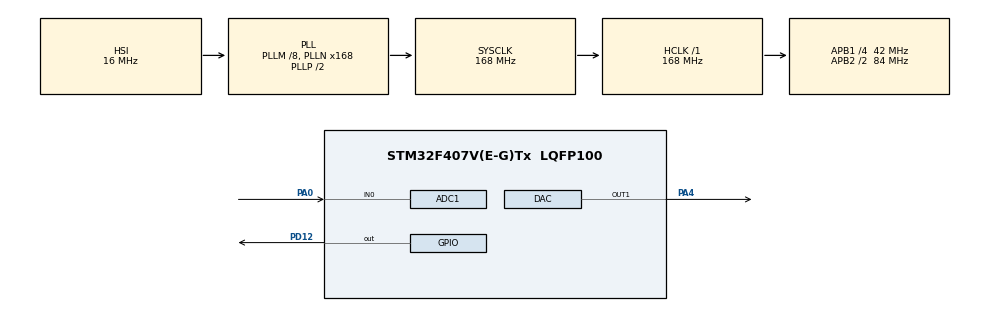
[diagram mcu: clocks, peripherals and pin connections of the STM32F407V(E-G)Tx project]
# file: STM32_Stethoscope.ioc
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ADC1.Channel-2\#ChannelRegularConversion=ADC_CHANNEL_0
ADC1.ExternalTrigConv=ADC_EXTERNALTRIGCONV_T2_TRGO
ADC1.NbrOfConversionFlag=1
ADC1.Rank-2\#ChannelRegularConversion=1
ADC1.SamplingTime-2\#ChannelRegularConversion=ADC_SAMPLETIME_3CYCLES
ADC1.master=1
DAC.DAC_Trigger=DAC_TRIGGER_T2_TRGO
Dma.ADC1.0.Direction=DMA_PERIPH_TO_MEMORY
Dma.ADC1.0.FIFOMode=DMA_FIFOMODE_DISABLE
Dma.ADC1.0.Instance=DMA2_Stream0
Dma.ADC1.0.MemDataAlignment=DMA_MDATAALIGN_WORD
Dma.ADC1.0.MemInc=DMA_MINC_ENABLE
Dma.ADC1.0.Mode=DMA_CIRCULAR
Dma.ADC1.0.PeriphDataAlignment=DMA_PDATAALIGN_WORD
Dma.ADC1.0.PeriphInc=DMA_PINC_DISABLE
Dma.ADC1.0.Priority=DMA_PRIORITY_HIGH
Dma.DAC1.1.Direction=DMA_MEMORY_TO_PERIPH
Dma.DAC1.1.FIFOMode=DMA_FIFOMODE_DISABLE
Dma.DAC1.1.Instance=DMA1_Stream5
Dma.DAC1.1.MemDataAlignment=DMA_MDATAALIGN_WORD
Dma.DAC1.1.MemInc=DMA_MINC_ENABLE
Dma.DAC1.1.Mode=DMA_CIRCULAR
Dma.DAC1.1.PeriphDataAlignment=DMA_PDATAALIGN_WORD
Dma.DAC1.1.PeriphInc=DMA_PINC_DISABLE
Dma.DAC1.1.Priority=DMA_PRIORITY_HIGH
Dma.Request0=ADC1
Dma.Request1=DAC1
Mcu.Family=STM32F4
Mcu.Name=STM32F407V(E-G)Tx
Mcu.Package=LQFP100
NVIC.DMA1_Stream5_IRQn=true\:0\:0\:false\:false\:true\:false\:true
NVIC.DMA2_Stream0_IRQn=true\:0\:0\:false\:false\:true\:false\:true
NVIC.PriorityGroup=NVIC_PRIORITYGROUP_0
PA0-WKUP.Signal=ADCx_IN0
PA4.Signal=COMP_DAC1_group
PD12.Signal=GPIO_Output
ProjectManager.HeapSize=0x200
ProjectManager.StackSize=0x400
ProjectManager.TargetToolchain=MDK-ARM V5
RCC.48MHZClocksFreq_Value=48000000
RCC.AHBFreq_Value=168000000
RCC.APB1CLKDivider=RCC_HCLK_DIV4
RCC.APB1Freq_Value=42000000
RCC.APB1TimFreq_Value=84000000
RCC.APB2CLKDivider=RCC_HCLK_DIV2
RCC.APB2Freq_Value=84000000
RCC.APB2TimFreq_Value=168000000
RCC.CortexFreq_Value=168000000
RCC.HCLKFreq_Value=168000000
RCC.HSE_VALUE=8000000
RCC.HSI_VALUE=16000000
RCC.PLLM=8
RCC.PLLN=168
RCC.PLLQ=7
RCC.SYSCLKFreq_VALUE=168000000
RCC.SYSCLKSource=RCC_SYSCLKSOURCE_PLLCLK
RCC.VCOOutputFreq_Value=336000000
SH.ADCx_IN0.0=ADC1_IN0,IN0
SH.COMP_DAC1_group.0=DAC_OUT1,DAC_OUT1
TIM2.Period=874
TIM2.TIM_MasterOutputTrigger=TIM_TRGO_UPDATE
VP_TIM2_VS_ClockSourceINT.Mode=Internal
board=STM32F407G-DISC1

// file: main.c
/* USER CODE BEGIN Header */
/**
  ******************************************************************************
  * @file           : main.c
  * @brief          : Main program body
  ******************************************************************************
  * @attention
  *
  * <h2><center>&copy; Copyright (c) 2019 STMicroelectronics.
  * All rights reserved.</center></h2>
  *
  * This software component is licensed by ST under BSD 3-Clause license,
  * the "License"; You may not use this file except in compliance with the
  * License. You may obtain a copy of the License at:
  *                        opensource.org/licenses/BSD-3-Clause
  *
  ******************************************************************************
  */
/* USER CODE END Header */

#include "main.h"

/* USER CODE BEGIN PM */
#define DATASIZE 128
#define FULLBUFFERSIZE 256
/* USER CODE END PM */

ADC_HandleTypeDef hadc1;
DMA_HandleTypeDef hdma_adc1;

DAC_HandleTypeDef hdac;
DMA_HandleTypeDef hdma_dac1;

TIM_HandleTypeDef htim2;

/* USER CODE BEGIN PV */
uint32_t adcData[FULLBUFFERSIZE];
uint32_t dacData[FULLBUFFERSIZE];

static volatile uint32_t* inbufPtr;
static volatile uint32_t* outbufPtr;
/* USER CODE END PV */

void SystemClock_Config(void);
static void MX_GPIO_Init(void);
static void MX_DMA_Init(void);
static void MX_ADC1_Init(void);
static void MX_DAC_Init(void);
static void MX_TIM2_Init(void);

/* USER CODE BEGIN 0 */
void HAL_ADC_ConvHalfCpltCallback(ADC_HandleTypeDef* hadc)
{
  inbufPtr = &adcData[0];
	outbufPtr = &dacData[DATASIZE];
}

void HAL_ADC_ConvCpltCallback(ADC_HandleTypeDef* hadc)
{
	inbufPtr = &adcData[DATASIZE];
	outbufPtr = &dacData[0];
}

void processDSP()
{
	for(int n = 0; n < DATASIZE; n++)
	{
		outbufPtr[n] = inbufPtr[n];
	}
}
/* USER CODE END 0 */

int main(void)
{

  /* MCU Configuration--------------------------------------------------------*/

  /* Reset of all peripherals, Initializes the Flash interface and the Systick. */
  HAL_Init();

  /* Configure the system clock */
  SystemClock_Config();

  /* Initialize all configured peripherals */
  MX_GPIO_Init();
  MX_DMA_Init();
  MX_ADC1_Init();
  MX_DAC_Init();
  MX_TIM2_Init();
  /* USER CODE BEGIN 2 */
	HAL_TIM_Base_Start(&htim2);
	HAL_ADC_Start_DMA(&hadc1, (uint32_t *) adcData, FULLBUFFERSIZE);
	HAL_DAC_Start_DMA(&hdac, DAC_CHANNEL_1, (uint32_t *) dacData, FULLBUFFERSIZE, DAC_ALIGN_12B_R);
  /* USER CODE END 2 */

  /* Infinite loop */
  while (1)
  {
		processDSP();
  }
}

void SystemClock_Config(void)
{
  RCC_OscInitTypeDef RCC_OscInitStruct = {0};
  RCC_ClkInitTypeDef RCC_ClkInitStruct = {0};

  /** Configure the main internal regulator output voltage
  */
  __HAL_RCC_PWR_CLK_ENABLE();
  __HAL_PWR_VOLTAGESCALING_CONFIG(PWR_REGULATOR_VOLTAGE_SCALE1);
  /** Initializes the CPU, AHB and APB busses clocks
  */
  RCC_OscInitStruct.OscillatorType = RCC_OSCILLATORTYPE_HSI;
  RCC_OscInitStruct.HSIState = RCC_HSI_ON;
  RCC_OscInitStruct.HSICalibrationValue = RCC_HSICALIBRATION_DEFAULT;
  RCC_OscInitStruct.PLL.PLLState = RCC_PLL_ON;
  RCC_OscInitStruct.PLL.PLLSource = RCC_PLLSOURCE_HSI;
  RCC_OscInitStruct.PLL.PLLM = 8;
  RCC_OscInitStruct.PLL.PLLN = 168;
  RCC_OscInitStruct.PLL.PLLP = RCC_PLLP_DIV2;
  RCC_OscInitStruct.PLL.PLLQ = 7;
  if (HAL_RCC_OscConfig(&RCC_OscInitStruct) != HAL_OK)
  {
    Error_Handler();
  }
  /** Initializes the CPU, AHB and APB busses clocks
  */
  RCC_ClkInitStruct.ClockType = RCC_CLOCKTYPE_HCLK|RCC_CLOCKTYPE_SYSCLK
                              |RCC_CLOCKTYPE_PCLK1|RCC_CLOCKTYPE_PCLK2;
  RCC_ClkInitStruct.SYSCLKSource = RCC_SYSCLKSOURCE_PLLCLK;
  RCC_ClkInitStruct.AHBCLKDivider = RCC_SYSCLK_DIV1;
  RCC_ClkInitStruct.APB1CLKDivider = RCC_HCLK_DIV4;
  RCC_ClkInitStruct.APB2CLKDivider = RCC_HCLK_DIV2;

  if (HAL_RCC_ClockConfig(&RCC_ClkInitStruct, FLASH_LATENCY_5) != HAL_OK)
  {
    Error_Handler();
  }
}

static void MX_ADC1_Init(void)
{

  ADC_ChannelConfTypeDef sConfig = {0};

  /** Configure the global features of the ADC (Clock, Resolution, Data Alignment and number of conversion)
  */
  hadc1.Instance = ADC1;
  hadc1.Init.ClockPrescaler = ADC_CLOCK_SYNC_PCLK_DIV4;
  hadc1.Init.Resolution = ADC_RESOLUTION_12B;
  hadc1.Init.ScanConvMode = DISABLE;
  hadc1.Init.ContinuousConvMode = DISABLE;
  hadc1.Init.DiscontinuousConvMode = DISABLE;
  hadc1.Init.ExternalTrigConvEdge = ADC_EXTERNALTRIGCONVEDGE_RISING;
  hadc1.Init.ExternalTrigConv = ADC_EXTERNALTRIGCONV_T2_TRGO;
  hadc1.Init.DataAlign = ADC_DATAALIGN_RIGHT;
  hadc1.Init.NbrOfConversion = 1;
  hadc1.Init.DMAContinuousRequests = ENABLE;
  hadc1.Init.EOCSelection = ADC_EOC_SINGLE_CONV;
  if (HAL_ADC_Init(&hadc1) != HAL_OK)
  {
    Error_Handler();
  }
  /** Configure for the selected ADC regular channel its corresponding rank in the sequencer and its sample time.
  */
  sConfig.Channel = ADC_CHANNEL_0;
  sConfig.Rank = 1;
  sConfig.SamplingTime = ADC_SAMPLETIME_3CYCLES;
  if (HAL_ADC_ConfigChannel(&hadc1, &sConfig) != HAL_OK)
  {
    Error_Handler();
  }

}

static void MX_DAC_Init(void)
{

  DAC_ChannelConfTypeDef sConfig = {0};

  /** DAC Initialization
  */
  hdac.Instance = DAC;
  if (HAL_DAC_Init(&hdac) != HAL_OK)
  {
    Error_Handler();
  }
  /** DAC channel OUT1 config
  */
  sConfig.DAC_Trigger = DAC_TRIGGER_T2_TRGO;
  sConfig.DAC_OutputBuffer = DAC_OUTPUTBUFFER_ENABLE;
  if (HAL_DAC_ConfigChannel(&hdac, &sConfig, DAC_CHANNEL_1) != HAL_OK)
  {
    Error_Handler();
  }

}

static void MX_TIM2_Init(void)
{

  TIM_ClockConfigTypeDef sClockSourceConfig = {0};
  TIM_MasterConfigTypeDef sMasterConfig = {0};

  htim2.Instance = TIM2;
  htim2.Init.Prescaler = 0;
  htim2.Init.CounterMode = TIM_COUNTERMODE_UP;
  htim2.Init.Period = 874;
  htim2.Init.ClockDivision = TIM_CLOCKDIVISION_DIV1;
  htim2.Init.AutoReloadPreload = TIM_AUTORELOAD_PRELOAD_DISABLE;
  if (HAL_TIM_Base_Init(&htim2) != HAL_OK)
  {
    Error_Handler();
  }
  sClockSourceConfig.ClockSource = TIM_CLOCKSOURCE_INTERNAL;
  if (HAL_TIM_ConfigClockSource(&htim2, &sClockSourceConfig) != HAL_OK)
  {
    Error_Handler();
  }
  sMasterConfig.MasterOutputTrigger = TIM_TRGO_UPDATE;
  sMasterConfig.MasterSlaveMode = TIM_MASTERSLAVEMODE_DISABLE;
  if (HAL_TIMEx_MasterConfigSynchronization(&htim2, &sMasterConfig) != HAL_OK)
  {
    Error_Handler();
  }

}

static void MX_DMA_Init(void)
{

  /* DMA controller clock enable */
  __HAL_RCC_DMA2_CLK_ENABLE();
  __HAL_RCC_DMA1_CLK_ENABLE();

  /* DMA interrupt init */
  /* DMA1_Stream5_IRQn interrupt configuration */
  HAL_NVIC_SetPriority(DMA1_Stream5_IRQn, 0, 0);
  HAL_NVIC_EnableIRQ(DMA1_Stream5_IRQn);
  /* DMA2_Stream0_IRQn interrupt configuration */
  HAL_NVIC_SetPriority(DMA2_Stream0_IRQn, 0, 0);
  HAL_NVIC_EnableIRQ(DMA2_Stream0_IRQn);

}

static void MX_GPIO_Init(void)
{
  GPIO_InitTypeDef GPIO_InitStruct = {0};

  /* GPIO Ports Clock Enable */
  __HAL_RCC_GPIOA_CLK_ENABLE();
  __HAL_RCC_GPIOD_CLK_ENABLE();

  /*Configure GPIO pin Output Level */
  HAL_GPIO_WritePin(GPIOD, GPIO_PIN_12, GPIO_PIN_RESET);

  /*Configure GPIO pin : PD12 */
  GPIO_InitStruct.Pin = GPIO_PIN_12;
  GPIO_InitStruct.Mode = GPIO_MODE_OUTPUT_PP;
  GPIO_InitStruct.Pull = GPIO_NOPULL;
  GPIO_InitStruct.Speed = GPIO_SPEED_FREQ_LOW;
  HAL_GPIO_Init(GPIOD, &GPIO_InitStruct);

}

void Error_Handler(void)
{
}

/************************ (C) COPYRIGHT STMicroelectronics *****END OF FILE****/
